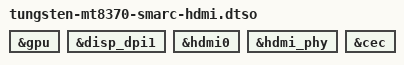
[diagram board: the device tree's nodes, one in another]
// SPDX-License-Identifier: (GPL-2.0 OR MIT)
/dts-v1/;
/plugin/;

&gpu {
	status = "okay";
};

&disp_dpi1 {
	status = "okay";
};

&hdmi0 {
	status = "okay";
};

&hdmi_phy {
	status = "okay";
};

&cec {
	status = "okay";
};
